# ESP32-P4-LP register map
Vendor: ESPRESSIF SYSTEMS (SHANGHAI) CO., LTD.; Series: ESP32 P-Series; File version: 3
CPU: RV32IMAC r0p0, little endian, no MPU, no FPU, 0 interrupt priority bits
Address unit: 32 bits
Registers are 32-bit, read-write, reset 0x0 unless marked. A register's access mark holds for its fields unless they carry their own. Offsets are from the block's base; [hi:lo] are bit positions; {n}, {i} and the like mark numbered series.

## PMU
Base 0x50115000
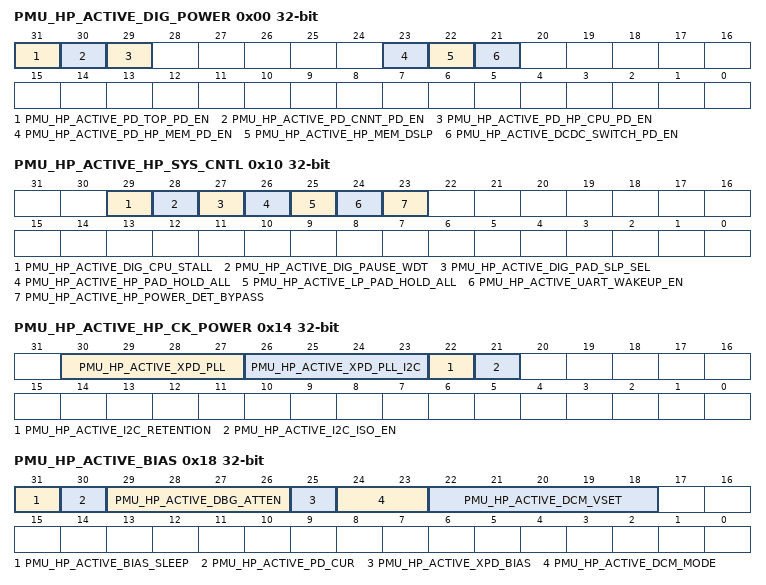
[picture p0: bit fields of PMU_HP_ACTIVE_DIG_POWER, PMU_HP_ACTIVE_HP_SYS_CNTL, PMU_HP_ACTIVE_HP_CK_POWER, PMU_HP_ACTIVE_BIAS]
0x00 PMU_HP_ACTIVE_DIG_POWER
  [31] PMU_HP_ACTIVE_PD_TOP_PD_EN, [30] PMU_HP_ACTIVE_PD_CNNT_PD_EN, [29] PMU_HP_ACTIVE_PD_HP_CPU_PD_EN, [23] PMU_HP_ACTIVE_PD_HP_MEM_PD_EN, [22] PMU_HP_ACTIVE_HP_MEM_DSLP, [21] PMU_HP_ACTIVE_DCDC_SWITCH_PD_EN
0x04 PMU_HP_ACTIVE_ICG_HP_FUNC
  [31:0] PMU_HP_ACTIVE_DIG_ICG_FUNC_EN
0x08 PMU_HP_ACTIVE_ICG_HP_APB
  [31:0] PMU_HP_ACTIVE_DIG_ICG_APB_EN
0x0C PMU_HP_ACTIVE_ICG_MODEM
  [31:30] PMU_HP_ACTIVE_DIG_ICG_MODEM_CODE
0x10 PMU_HP_ACTIVE_HP_SYS_CNTL
  [29] PMU_HP_ACTIVE_DIG_CPU_STALL, [28] PMU_HP_ACTIVE_DIG_PAUSE_WDT, [27] PMU_HP_ACTIVE_DIG_PAD_SLP_SEL, [26] PMU_HP_ACTIVE_HP_PAD_HOLD_ALL, [25] PMU_HP_ACTIVE_LP_PAD_HOLD_ALL, [24] PMU_HP_ACTIVE_UART_WAKEUP_EN, [23] PMU_HP_ACTIVE_HP_POWER_DET_BYPASS
0x14 PMU_HP_ACTIVE_HP_CK_POWER
  [30:27] PMU_HP_ACTIVE_XPD_PLL, [26:23] PMU_HP_ACTIVE_XPD_PLL_I2C, [22] PMU_HP_ACTIVE_I2C_RETENTION, [21] PMU_HP_ACTIVE_I2C_ISO_EN
0x18 PMU_HP_ACTIVE_BIAS
  [31] PMU_HP_ACTIVE_BIAS_SLEEP, [30] PMU_HP_ACTIVE_PD_CUR, [29:26] PMU_HP_ACTIVE_DBG_ATTEN, [25] PMU_HP_ACTIVE_XPD_BIAS, [24:23] PMU_HP_ACTIVE_DCM_MODE, [22:18] PMU_HP_ACTIVE_DCM_VSET
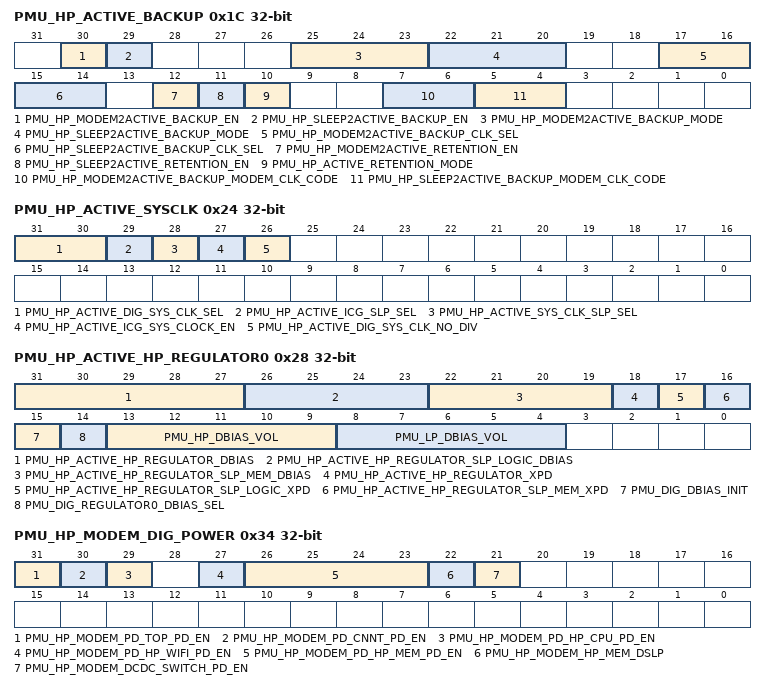
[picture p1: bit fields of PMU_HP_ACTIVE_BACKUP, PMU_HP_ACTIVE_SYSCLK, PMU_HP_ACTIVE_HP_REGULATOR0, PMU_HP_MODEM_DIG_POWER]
0x1C PMU_HP_ACTIVE_BACKUP
  [30] PMU_HP_MODEM2ACTIVE_BACKUP_EN, [29] PMU_HP_SLEEP2ACTIVE_BACKUP_EN, [25:23] PMU_HP_MODEM2ACTIVE_BACKUP_MODE, [22:20] PMU_HP_SLEEP2ACTIVE_BACKUP_MODE, [17:16] PMU_HP_MODEM2ACTIVE_BACKUP_CLK_SEL, [15:14] PMU_HP_SLEEP2ACTIVE_BACKUP_CLK_SEL, [12] PMU_HP_MODEM2ACTIVE_RETENTION_EN, [11] PMU_HP_SLEEP2ACTIVE_RETENTION_EN, [10] PMU_HP_ACTIVE_RETENTION_MODE, [7:6] PMU_HP_MODEM2ACTIVE_BACKUP_MODEM_CLK_CODE, [5:4] PMU_HP_SLEEP2ACTIVE_BACKUP_MODEM_CLK_CODE
0x20 PMU_HP_ACTIVE_BACKUP_CLK
  [31:0] PMU_HP_ACTIVE_BACKUP_ICG_FUNC_EN
0x24 PMU_HP_ACTIVE_SYSCLK
  [31:30] PMU_HP_ACTIVE_DIG_SYS_CLK_SEL, [29] PMU_HP_ACTIVE_ICG_SLP_SEL, [28] PMU_HP_ACTIVE_SYS_CLK_SLP_SEL, [27] PMU_HP_ACTIVE_ICG_SYS_CLOCK_EN, [26] PMU_HP_ACTIVE_DIG_SYS_CLK_NO_DIV
0x28 PMU_HP_ACTIVE_HP_REGULATOR0 access per field
  [31:27] PMU_HP_ACTIVE_HP_REGULATOR_DBIAS rw, [26:23] PMU_HP_ACTIVE_HP_REGULATOR_SLP_LOGIC_DBIAS rw, [22:19] PMU_HP_ACTIVE_HP_REGULATOR_SLP_MEM_DBIAS rw, [18] PMU_HP_ACTIVE_HP_REGULATOR_XPD rw, [17] PMU_HP_ACTIVE_HP_REGULATOR_SLP_LOGIC_XPD rw, [16] PMU_HP_ACTIVE_HP_REGULATOR_SLP_MEM_XPD rw, [15] PMU_DIG_DBIAS_INIT wo, [14] PMU_DIG_REGULATOR0_DBIAS_SEL rw, [13:9] PMU_HP_DBIAS_VOL ro, [8:4] PMU_LP_DBIAS_VOL ro
0x2C PMU_HP_ACTIVE_HP_REGULATOR1
  [31:26] PMU_HP_ACTIVE_HP_REGULATOR_DRV_B
0x30 PMU_HP_ACTIVE_XTAL
  [31] PMU_HP_ACTIVE_XPD_XTAL
0x34 PMU_HP_MODEM_DIG_POWER access per field
  [31] PMU_HP_MODEM_PD_TOP_PD_EN wo, [30] PMU_HP_MODEM_PD_CNNT_PD_EN wo, [29] PMU_HP_MODEM_PD_HP_CPU_PD_EN wo, [27] PMU_HP_MODEM_PD_HP_WIFI_PD_EN wo, [26:23] PMU_HP_MODEM_PD_HP_MEM_PD_EN wo, [22] PMU_HP_MODEM_HP_MEM_DSLP wo, [21] PMU_HP_MODEM_DCDC_SWITCH_PD_EN rw
0x38 PMU_HP_MODEM_ICG_HP_FUNC wo
  [31:0] PMU_HP_MODEM_DIG_ICG_FUNC_EN
0x3C PMU_HP_MODEM_ICG_HP_APB wo
  [31:0] PMU_HP_MODEM_DIG_ICG_APB_EN
0x40 PMU_HP_MODEM_ICG_MODEM wo
  [31:30] PMU_HP_MODEM_DIG_ICG_MODEM_CODE
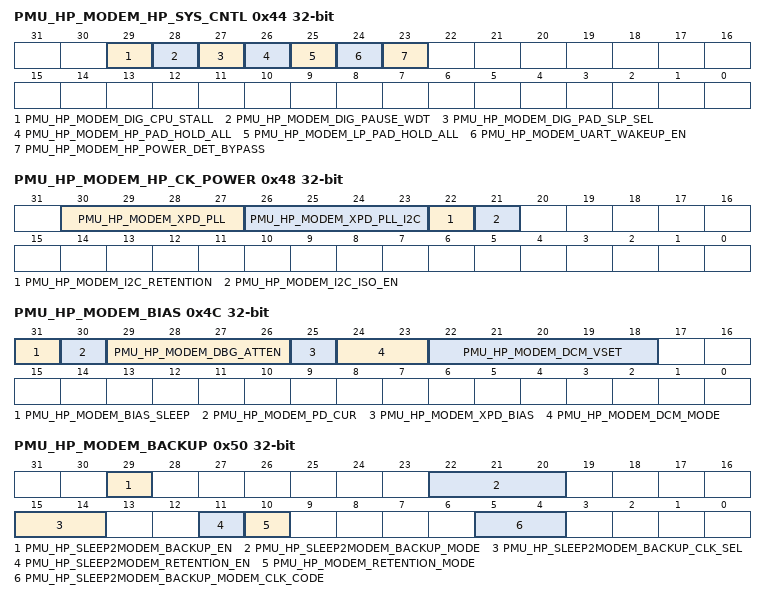
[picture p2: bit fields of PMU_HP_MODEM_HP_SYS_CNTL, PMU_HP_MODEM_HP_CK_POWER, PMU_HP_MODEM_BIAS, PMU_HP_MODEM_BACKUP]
0x44 PMU_HP_MODEM_HP_SYS_CNTL wo
  [29] PMU_HP_MODEM_DIG_CPU_STALL, [28] PMU_HP_MODEM_DIG_PAUSE_WDT, [27] PMU_HP_MODEM_DIG_PAD_SLP_SEL, [26] PMU_HP_MODEM_HP_PAD_HOLD_ALL, [25] PMU_HP_MODEM_LP_PAD_HOLD_ALL, [24] PMU_HP_MODEM_UART_WAKEUP_EN, [23] PMU_HP_MODEM_HP_POWER_DET_BYPASS
0x48 PMU_HP_MODEM_HP_CK_POWER wo
  [30:27] PMU_HP_MODEM_XPD_PLL, [26:23] PMU_HP_MODEM_XPD_PLL_I2C, [22] PMU_HP_MODEM_I2C_RETENTION, [21] PMU_HP_MODEM_I2C_ISO_EN
0x4C PMU_HP_MODEM_BIAS wo
  [31] PMU_HP_MODEM_BIAS_SLEEP, [30] PMU_HP_MODEM_PD_CUR, [29:26] PMU_HP_MODEM_DBG_ATTEN, [25] PMU_HP_MODEM_XPD_BIAS, [24:23] PMU_HP_MODEM_DCM_MODE, [22:18] PMU_HP_MODEM_DCM_VSET
0x50 PMU_HP_MODEM_BACKUP wo
  [29] PMU_HP_SLEEP2MODEM_BACKUP_EN, [22:20] PMU_HP_SLEEP2MODEM_BACKUP_MODE, [15:14] PMU_HP_SLEEP2MODEM_BACKUP_CLK_SEL, [11] PMU_HP_SLEEP2MODEM_RETENTION_EN, [10] PMU_HP_MODEM_RETENTION_MODE, [5:4] PMU_HP_SLEEP2MODEM_BACKUP_MODEM_CLK_CODE
0x54 PMU_HP_MODEM_BACKUP_CLK wo
  [31:0] PMU_HP_MODEM_BACKUP_ICG_FUNC_EN
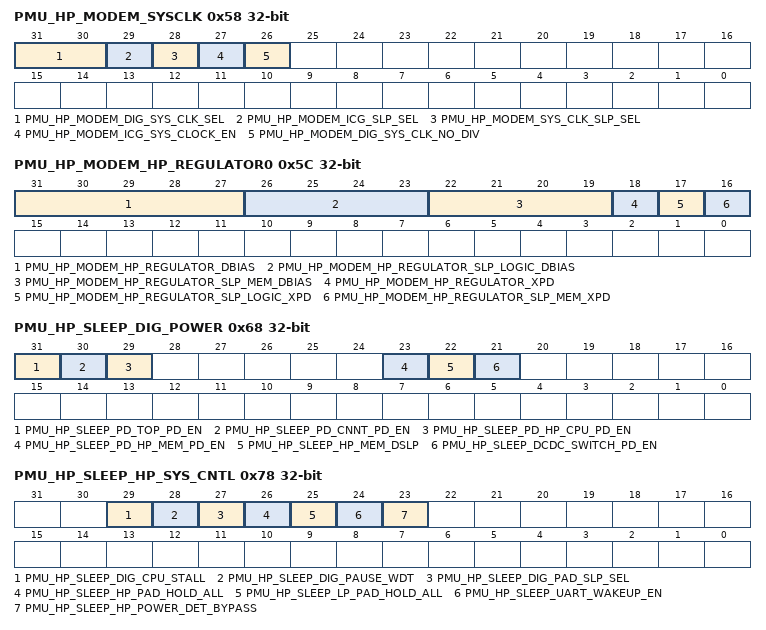
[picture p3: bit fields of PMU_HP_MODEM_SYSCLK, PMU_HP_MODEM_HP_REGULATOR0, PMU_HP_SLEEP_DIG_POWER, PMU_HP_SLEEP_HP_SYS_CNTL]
0x58 PMU_HP_MODEM_SYSCLK wo
  [31:30] PMU_HP_MODEM_DIG_SYS_CLK_SEL, [29] PMU_HP_MODEM_ICG_SLP_SEL, [28] PMU_HP_MODEM_SYS_CLK_SLP_SEL, [27] PMU_HP_MODEM_ICG_SYS_CLOCK_EN, [26] PMU_HP_MODEM_DIG_SYS_CLK_NO_DIV
0x5C PMU_HP_MODEM_HP_REGULATOR0 wo
  [31:27] PMU_HP_MODEM_HP_REGULATOR_DBIAS, [26:23] PMU_HP_MODEM_HP_REGULATOR_SLP_LOGIC_DBIAS, [22:19] PMU_HP_MODEM_HP_REGULATOR_SLP_MEM_DBIAS, [18] PMU_HP_MODEM_HP_REGULATOR_XPD, [17] PMU_HP_MODEM_HP_REGULATOR_SLP_LOGIC_XPD, [16] PMU_HP_MODEM_HP_REGULATOR_SLP_MEM_XPD
0x60 PMU_HP_MODEM_HP_REGULATOR1 wo
  [31:8] PMU_HP_MODEM_HP_REGULATOR_DRV_B
0x64 PMU_HP_MODEM_XTAL wo
  [31] PMU_HP_MODEM_XPD_XTAL
0x68 PMU_HP_SLEEP_DIG_POWER
  [31] PMU_HP_SLEEP_PD_TOP_PD_EN, [30] PMU_HP_SLEEP_PD_CNNT_PD_EN, [29] PMU_HP_SLEEP_PD_HP_CPU_PD_EN, [23] PMU_HP_SLEEP_PD_HP_MEM_PD_EN, [22] PMU_HP_SLEEP_HP_MEM_DSLP, [21] PMU_HP_SLEEP_DCDC_SWITCH_PD_EN
0x6C PMU_HP_SLEEP_ICG_HP_FUNC
  [31:0] PMU_HP_SLEEP_DIG_ICG_FUNC_EN
0x70 PMU_HP_SLEEP_ICG_HP_APB
  [31:0] PMU_HP_SLEEP_DIG_ICG_APB_EN
0x74 PMU_HP_SLEEP_ICG_MODEM
  [31:30] PMU_HP_SLEEP_DIG_ICG_MODEM_CODE
0x78 PMU_HP_SLEEP_HP_SYS_CNTL
  [29] PMU_HP_SLEEP_DIG_CPU_STALL, [28] PMU_HP_SLEEP_DIG_PAUSE_WDT, [27] PMU_HP_SLEEP_DIG_PAD_SLP_SEL, [26] PMU_HP_SLEEP_HP_PAD_HOLD_ALL, [25] PMU_HP_SLEEP_LP_PAD_HOLD_ALL, [24] PMU_HP_SLEEP_UART_WAKEUP_EN, [23] PMU_HP_SLEEP_HP_POWER_DET_BYPASS
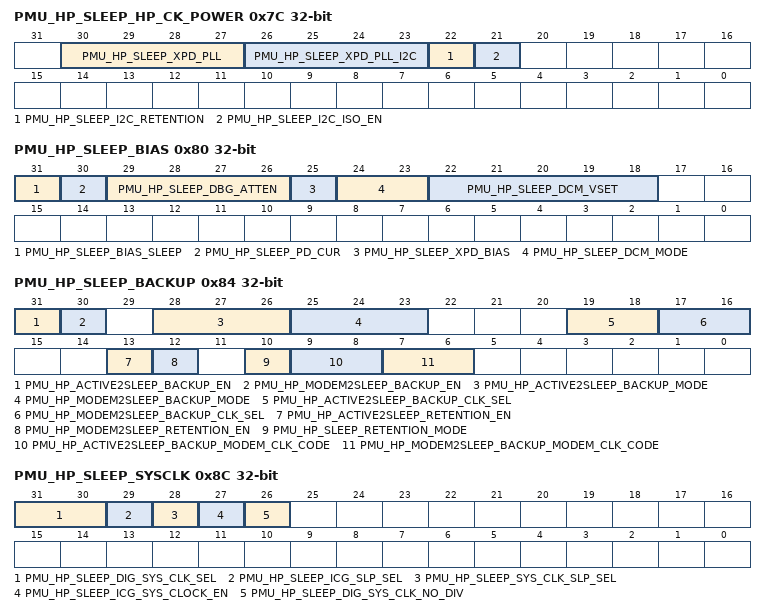
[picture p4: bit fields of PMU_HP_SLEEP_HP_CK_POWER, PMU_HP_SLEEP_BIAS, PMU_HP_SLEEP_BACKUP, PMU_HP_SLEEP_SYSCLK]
0x7C PMU_HP_SLEEP_HP_CK_POWER
  [30:27] PMU_HP_SLEEP_XPD_PLL, [26:23] PMU_HP_SLEEP_XPD_PLL_I2C, [22] PMU_HP_SLEEP_I2C_RETENTION, [21] PMU_HP_SLEEP_I2C_ISO_EN
0x80 PMU_HP_SLEEP_BIAS
  [31] PMU_HP_SLEEP_BIAS_SLEEP, [30] PMU_HP_SLEEP_PD_CUR, [29:26] PMU_HP_SLEEP_DBG_ATTEN, [25] PMU_HP_SLEEP_XPD_BIAS, [24:23] PMU_HP_SLEEP_DCM_MODE, [22:18] PMU_HP_SLEEP_DCM_VSET
0x84 PMU_HP_SLEEP_BACKUP
  [31] PMU_HP_ACTIVE2SLEEP_BACKUP_EN, [30] PMU_HP_MODEM2SLEEP_BACKUP_EN, [28:26] PMU_HP_ACTIVE2SLEEP_BACKUP_MODE, [25:23] PMU_HP_MODEM2SLEEP_BACKUP_MODE, [19:18] PMU_HP_ACTIVE2SLEEP_BACKUP_CLK_SEL, [17:16] PMU_HP_MODEM2SLEEP_BACKUP_CLK_SEL, [13] PMU_HP_ACTIVE2SLEEP_RETENTION_EN, [12] PMU_HP_MODEM2SLEEP_RETENTION_EN, [10] PMU_HP_SLEEP_RETENTION_MODE, [9:8] PMU_HP_ACTIVE2SLEEP_BACKUP_MODEM_CLK_CODE, [7:6] PMU_HP_MODEM2SLEEP_BACKUP_MODEM_CLK_CODE
0x88 PMU_HP_SLEEP_BACKUP_CLK
  [31:0] PMU_HP_SLEEP_BACKUP_ICG_FUNC_EN
0x8C PMU_HP_SLEEP_SYSCLK
  [31:30] PMU_HP_SLEEP_DIG_SYS_CLK_SEL, [29] PMU_HP_SLEEP_ICG_SLP_SEL, [28] PMU_HP_SLEEP_SYS_CLK_SLP_SEL, [27] PMU_HP_SLEEP_ICG_SYS_CLOCK_EN, [26] PMU_HP_SLEEP_DIG_SYS_CLK_NO_DIV
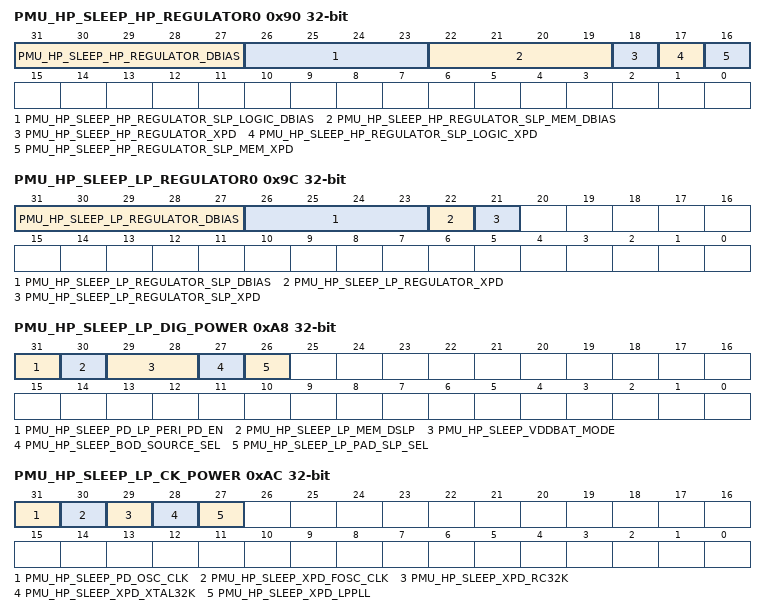
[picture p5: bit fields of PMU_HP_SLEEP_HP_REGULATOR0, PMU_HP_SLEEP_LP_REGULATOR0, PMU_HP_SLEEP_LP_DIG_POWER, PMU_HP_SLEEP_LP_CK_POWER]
0x90 PMU_HP_SLEEP_HP_REGULATOR0
  [31:27] PMU_HP_SLEEP_HP_REGULATOR_DBIAS, [26:23] PMU_HP_SLEEP_HP_REGULATOR_SLP_LOGIC_DBIAS, [22:19] PMU_HP_SLEEP_HP_REGULATOR_SLP_MEM_DBIAS, [18] PMU_HP_SLEEP_HP_REGULATOR_XPD, [17] PMU_HP_SLEEP_HP_REGULATOR_SLP_LOGIC_XPD, [16] PMU_HP_SLEEP_HP_REGULATOR_SLP_MEM_XPD
0x94 PMU_HP_SLEEP_HP_REGULATOR1
  [31:26] PMU_HP_SLEEP_HP_REGULATOR_DRV_B
0x98 PMU_HP_SLEEP_XTAL
  [31] PMU_HP_SLEEP_XPD_XTAL
0x9C PMU_HP_SLEEP_LP_REGULATOR0
  [31:27] PMU_HP_SLEEP_LP_REGULATOR_DBIAS, [26:23] PMU_HP_SLEEP_LP_REGULATOR_SLP_DBIAS, [22] PMU_HP_SLEEP_LP_REGULATOR_XPD, [21] PMU_HP_SLEEP_LP_REGULATOR_SLP_XPD
0xA0 PMU_HP_SLEEP_LP_REGULATOR1
  [31:26] PMU_HP_SLEEP_LP_REGULATOR_DRV_B
0xA8 PMU_HP_SLEEP_LP_DIG_POWER
  [31] PMU_HP_SLEEP_PD_LP_PERI_PD_EN, [30] PMU_HP_SLEEP_LP_MEM_DSLP, [29:28] PMU_HP_SLEEP_VDDBAT_MODE, [27] PMU_HP_SLEEP_BOD_SOURCE_SEL, [26] PMU_HP_SLEEP_LP_PAD_SLP_SEL
0xAC PMU_HP_SLEEP_LP_CK_POWER
  [31] PMU_HP_SLEEP_PD_OSC_CLK, [30] PMU_HP_SLEEP_XPD_FOSC_CLK, [29] PMU_HP_SLEEP_XPD_RC32K, [28] PMU_HP_SLEEP_XPD_XTAL32K, [27] PMU_HP_SLEEP_XPD_LPPLL
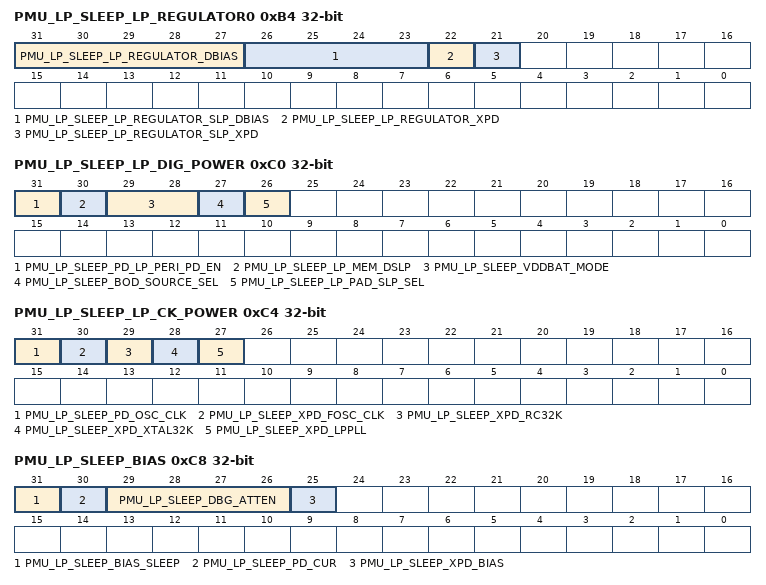
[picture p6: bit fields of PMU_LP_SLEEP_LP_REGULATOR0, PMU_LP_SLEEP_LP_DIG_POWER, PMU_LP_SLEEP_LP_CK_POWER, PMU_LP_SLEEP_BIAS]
0xB4 PMU_LP_SLEEP_LP_REGULATOR0
  [31:27] PMU_LP_SLEEP_LP_REGULATOR_DBIAS, [26:23] PMU_LP_SLEEP_LP_REGULATOR_SLP_DBIAS, [22] PMU_LP_SLEEP_LP_REGULATOR_XPD, [21] PMU_LP_SLEEP_LP_REGULATOR_SLP_XPD
0xB8 PMU_LP_SLEEP_LP_REGULATOR1
  [31:26] PMU_LP_SLEEP_LP_REGULATOR_DRV_B
0xBC PMU_LP_SLEEP_XTAL
  [31] PMU_LP_SLEEP_XPD_XTAL
0xC0 PMU_LP_SLEEP_LP_DIG_POWER
  [31] PMU_LP_SLEEP_PD_LP_PERI_PD_EN, [30] PMU_LP_SLEEP_LP_MEM_DSLP, [29:28] PMU_LP_SLEEP_VDDBAT_MODE, [27] PMU_LP_SLEEP_BOD_SOURCE_SEL, [26] PMU_LP_SLEEP_LP_PAD_SLP_SEL
0xC4 PMU_LP_SLEEP_LP_CK_POWER
  [31] PMU_LP_SLEEP_PD_OSC_CLK, [30] PMU_LP_SLEEP_XPD_FOSC_CLK, [29] PMU_LP_SLEEP_XPD_RC32K, [28] PMU_LP_SLEEP_XPD_XTAL32K, [27] PMU_LP_SLEEP_XPD_LPPLL
0xC8 PMU_LP_SLEEP_BIAS
  [31] PMU_LP_SLEEP_BIAS_SLEEP, [30] PMU_LP_SLEEP_PD_CUR, [29:26] PMU_LP_SLEEP_DBG_ATTEN, [25] PMU_LP_SLEEP_XPD_BIAS
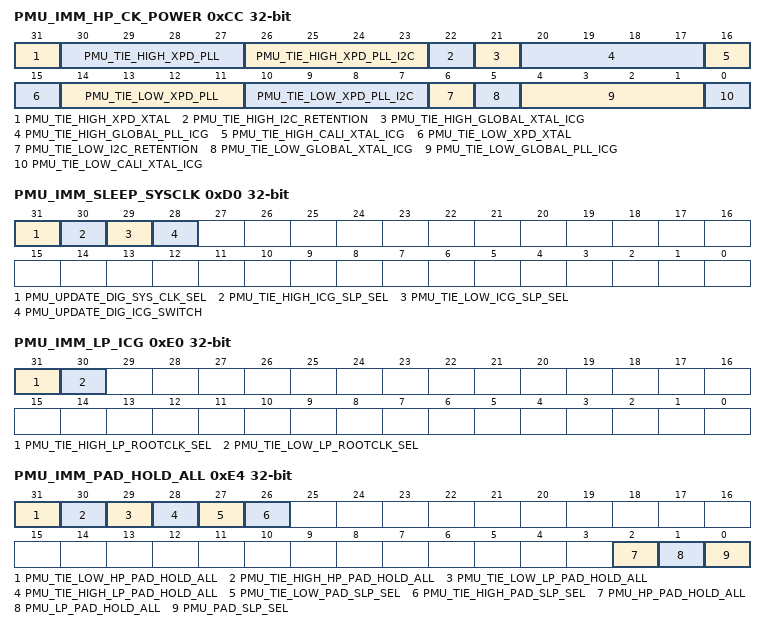
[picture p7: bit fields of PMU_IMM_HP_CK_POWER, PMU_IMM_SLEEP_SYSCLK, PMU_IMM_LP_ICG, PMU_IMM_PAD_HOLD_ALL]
0xCC PMU_IMM_HP_CK_POWER access per field
  [31] PMU_TIE_HIGH_XPD_XTAL wo, [30:27] PMU_TIE_HIGH_XPD_PLL wo, [26:23] PMU_TIE_HIGH_XPD_PLL_I2C wo, [22] PMU_TIE_HIGH_I2C_RETENTION wo, [21] PMU_TIE_HIGH_GLOBAL_XTAL_ICG wo, [20:17] PMU_TIE_HIGH_GLOBAL_PLL_ICG wo, [16] PMU_TIE_HIGH_CALI_XTAL_ICG rw, [15] PMU_TIE_LOW_XPD_XTAL wo, [14:11] PMU_TIE_LOW_XPD_PLL wo, [10:7] PMU_TIE_LOW_XPD_PLL_I2C wo, [6] PMU_TIE_LOW_I2C_RETENTION wo, [5] PMU_TIE_LOW_GLOBAL_XTAL_ICG wo, [4:1] PMU_TIE_LOW_GLOBAL_PLL_ICG wo, [0] PMU_TIE_LOW_CALI_XTAL_ICG rw
0xD0 PMU_IMM_SLEEP_SYSCLK wo
  [31] PMU_UPDATE_DIG_SYS_CLK_SEL, [30] PMU_TIE_HIGH_ICG_SLP_SEL, [29] PMU_TIE_LOW_ICG_SLP_SEL, [28] PMU_UPDATE_DIG_ICG_SWITCH
0xD4 PMU_IMM_HP_FUNC_ICG wo
  [31] PMU_UPDATE_DIG_ICG_FUNC_EN
0xD8 PMU_IMM_HP_APB_ICG wo
  [31] PMU_UPDATE_DIG_ICG_APB_EN
0xDC PMU_IMM_MODEM_ICG wo
  [31] PMU_UPDATE_DIG_ICG_MODEM_EN
0xE0 PMU_IMM_LP_ICG wo
  [31] PMU_TIE_HIGH_LP_ROOTCLK_SEL, [30] PMU_TIE_LOW_LP_ROOTCLK_SEL
0xE4 PMU_IMM_PAD_HOLD_ALL access per field
  [31] PMU_TIE_LOW_HP_PAD_HOLD_ALL wo, [30] PMU_TIE_HIGH_HP_PAD_HOLD_ALL wo, [29] PMU_TIE_LOW_LP_PAD_HOLD_ALL wo, [28] PMU_TIE_HIGH_LP_PAD_HOLD_ALL wo, [27] PMU_TIE_LOW_PAD_SLP_SEL wo, [26] PMU_TIE_HIGH_PAD_SLP_SEL wo, [2] PMU_HP_PAD_HOLD_ALL ro, [1] PMU_LP_PAD_HOLD_ALL ro, [0] PMU_PAD_SLP_SEL ro
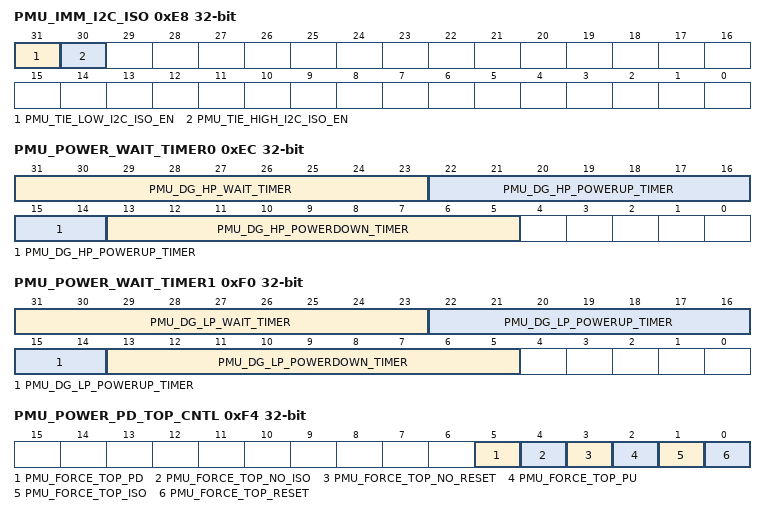
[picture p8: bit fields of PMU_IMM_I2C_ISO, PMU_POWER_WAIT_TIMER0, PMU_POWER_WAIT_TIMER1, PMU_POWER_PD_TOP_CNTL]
0xE8 PMU_IMM_I2C_ISO wo
  [31] PMU_TIE_LOW_I2C_ISO_EN, [30] PMU_TIE_HIGH_I2C_ISO_EN
0xEC PMU_POWER_WAIT_TIMER0
  [31:23] PMU_DG_HP_WAIT_TIMER, [22:14] PMU_DG_HP_POWERUP_TIMER, [13:5] PMU_DG_HP_POWERDOWN_TIMER
0xF0 PMU_POWER_WAIT_TIMER1
  [31:23] PMU_DG_LP_WAIT_TIMER, [22:14] PMU_DG_LP_POWERUP_TIMER, [13:5] PMU_DG_LP_POWERDOWN_TIMER
0xF4 PMU_POWER_PD_TOP_CNTL
  [5] PMU_FORCE_TOP_PD, [4] PMU_FORCE_TOP_NO_ISO, [3] PMU_FORCE_TOP_NO_RESET, [2] PMU_FORCE_TOP_PU, [1] PMU_FORCE_TOP_ISO, [0] PMU_FORCE_TOP_RESET
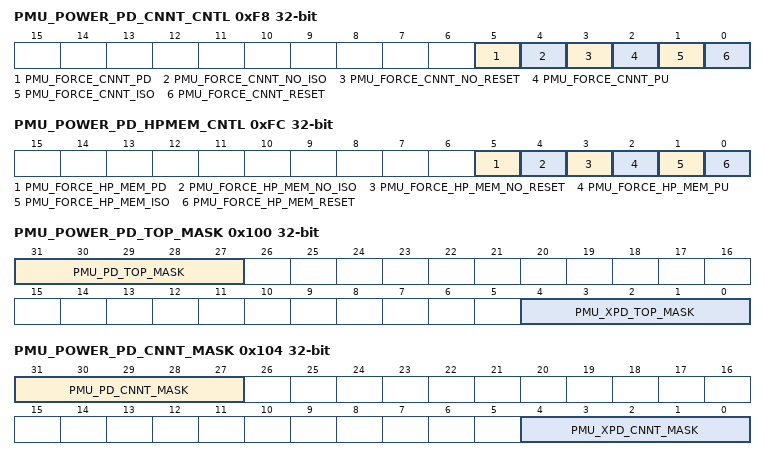
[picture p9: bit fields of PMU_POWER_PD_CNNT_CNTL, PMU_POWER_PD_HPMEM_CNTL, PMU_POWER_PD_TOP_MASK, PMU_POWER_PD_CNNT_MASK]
0xF8 PMU_POWER_PD_CNNT_CNTL
  [5] PMU_FORCE_CNNT_PD, [4] PMU_FORCE_CNNT_NO_ISO, [3] PMU_FORCE_CNNT_NO_RESET, [2] PMU_FORCE_CNNT_PU, [1] PMU_FORCE_CNNT_ISO, [0] PMU_FORCE_CNNT_RESET
0xFC PMU_POWER_PD_HPMEM_CNTL
  [5] PMU_FORCE_HP_MEM_PD, [4] PMU_FORCE_HP_MEM_NO_ISO, [3] PMU_FORCE_HP_MEM_NO_RESET, [2] PMU_FORCE_HP_MEM_PU, [1] PMU_FORCE_HP_MEM_ISO, [0] PMU_FORCE_HP_MEM_RESET
0x100 PMU_POWER_PD_TOP_MASK
  [31:27] PMU_PD_TOP_MASK, [4:0] PMU_XPD_TOP_MASK
0x104 PMU_POWER_PD_CNNT_MASK
  [31:27] PMU_PD_CNNT_MASK, [4:0] PMU_XPD_CNNT_MASK
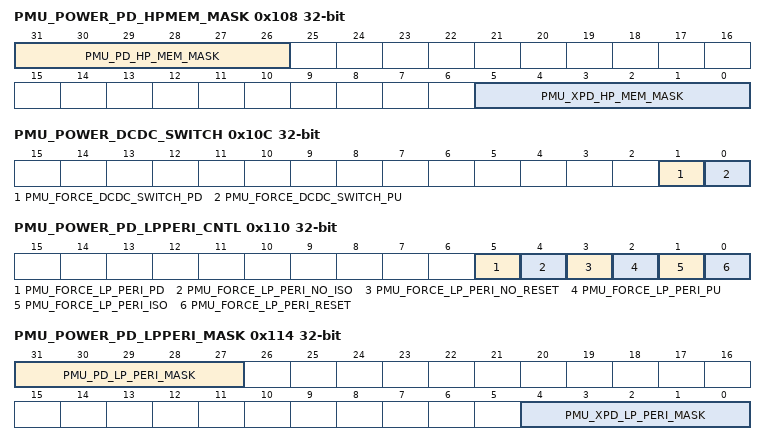
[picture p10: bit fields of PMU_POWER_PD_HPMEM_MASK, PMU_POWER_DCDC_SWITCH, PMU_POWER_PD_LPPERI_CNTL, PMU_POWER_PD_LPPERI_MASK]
0x108 PMU_POWER_PD_HPMEM_MASK
  [31:26] PMU_PD_HP_MEM_MASK, [5:0] PMU_XPD_HP_MEM_MASK
0x10C PMU_POWER_DCDC_SWITCH
  [1] PMU_FORCE_DCDC_SWITCH_PD, [0] PMU_FORCE_DCDC_SWITCH_PU
0x110 PMU_POWER_PD_LPPERI_CNTL
  [5] PMU_FORCE_LP_PERI_PD, [4] PMU_FORCE_LP_PERI_NO_ISO, [3] PMU_FORCE_LP_PERI_NO_RESET, [2] PMU_FORCE_LP_PERI_PU, [1] PMU_FORCE_LP_PERI_ISO, [0] PMU_FORCE_LP_PERI_RESET
0x114 PMU_POWER_PD_LPPERI_MASK
  [31:27] PMU_PD_LP_PERI_MASK, [4:0] PMU_XPD_LP_PERI_MASK
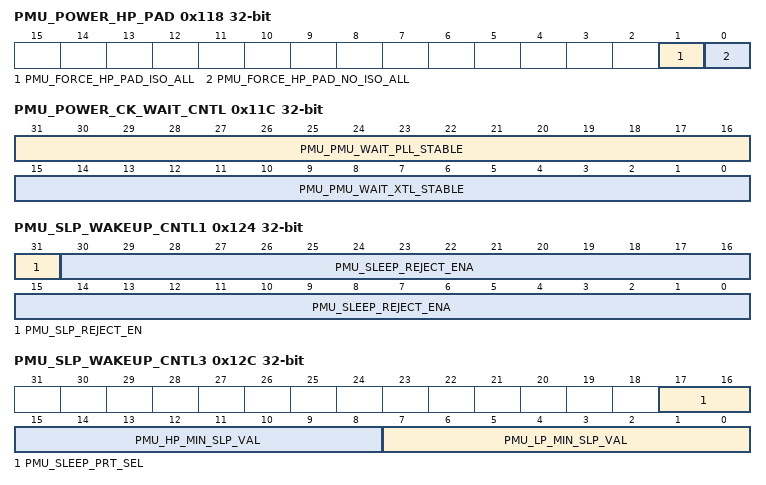
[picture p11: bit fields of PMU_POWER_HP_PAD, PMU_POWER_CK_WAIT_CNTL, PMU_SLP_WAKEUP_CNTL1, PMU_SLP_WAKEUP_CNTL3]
0x118 PMU_POWER_HP_PAD
  [1] PMU_FORCE_HP_PAD_ISO_ALL, [0] PMU_FORCE_HP_PAD_NO_ISO_ALL
0x11C PMU_POWER_CK_WAIT_CNTL
  [31:16] PMU_PMU_WAIT_PLL_STABLE, [15:0] PMU_PMU_WAIT_XTL_STABLE
0x120 PMU_SLP_WAKEUP_CNTL0 wo
  [31] PMU_SLEEP_REQ
0x124 PMU_SLP_WAKEUP_CNTL1
  [31] PMU_SLP_REJECT_EN, [30:0] PMU_SLEEP_REJECT_ENA
0x128 PMU_SLP_WAKEUP_CNTL2
  [30:0] PMU_WAKEUP_ENA
0x12C PMU_SLP_WAKEUP_CNTL3
  [17:16] PMU_SLEEP_PRT_SEL, [15:8] PMU_HP_MIN_SLP_VAL, [7:0] PMU_LP_MIN_SLP_VAL
0x130 PMU_SLP_WAKEUP_CNTL4 wo
  [31] PMU_SLP_REJECT_CAUSE_CLR
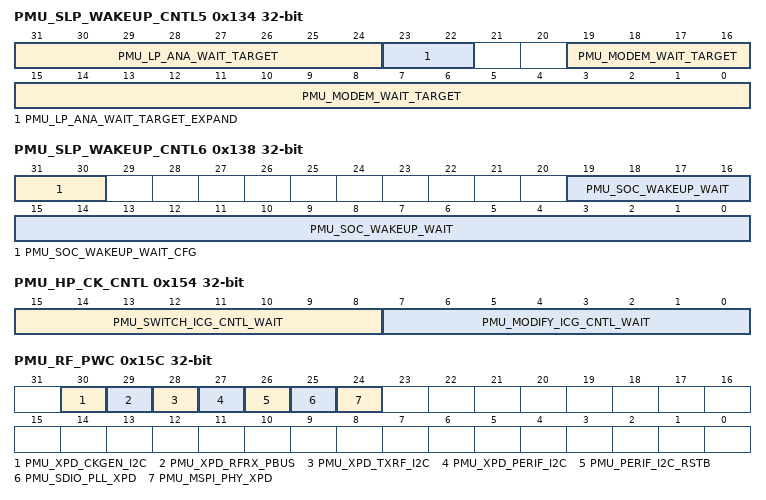
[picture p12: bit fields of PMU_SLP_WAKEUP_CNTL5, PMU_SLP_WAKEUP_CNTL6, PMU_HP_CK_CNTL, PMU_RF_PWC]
0x134 PMU_SLP_WAKEUP_CNTL5
  [31:24] PMU_LP_ANA_WAIT_TARGET, [23:22] PMU_LP_ANA_WAIT_TARGET_EXPAND, [19:0] PMU_MODEM_WAIT_TARGET
0x138 PMU_SLP_WAKEUP_CNTL6
  [31:30] PMU_SOC_WAKEUP_WAIT_CFG, [19:0] PMU_SOC_WAKEUP_WAIT
0x13C PMU_SLP_WAKEUP_CNTL7
  [31:16] PMU_ANA_WAIT_TARGET
0x140 PMU_SLP_WAKEUP_CNTL8
  [31] PMU_LP_LITE_WAKEUP_ENA
0x144 PMU_SLP_WAKEUP_STATUS0 ro
  [30:0] PMU_WAKEUP_CAUSE
0x148 PMU_SLP_WAKEUP_STATUS1 ro
  [30:0] PMU_REJECT_CAUSE
0x14C PMU_SLP_WAKEUP_STATUS2 ro
  [31] PMU_LP_LITE_WAKEUP_CAUSE
0x150 PMU_HP_CK_POWERON
  [7:0] PMU_I2C_POR_WAIT_TARGET
0x154 PMU_HP_CK_CNTL
  [15:8] PMU_SWITCH_ICG_CNTL_WAIT, [7:0] PMU_MODIFY_ICG_CNTL_WAIT
0x158 PMU_POR_STATUS ro
  [31] PMU_POR_DONE
0x15C PMU_RF_PWC
  [30] PMU_XPD_CKGEN_I2C, [29] PMU_XPD_RFRX_PBUS, [28] PMU_XPD_TXRF_I2C, [27] PMU_XPD_PERIF_I2C, [26] PMU_PERIF_I2C_RSTB, [25] PMU_SDIO_PLL_XPD, [24] PMU_MSPI_PHY_XPD
0x160 PMU_BACKUP_CFG
  [31] PMU_BACKUP_SYS_CLK_NO_DIV
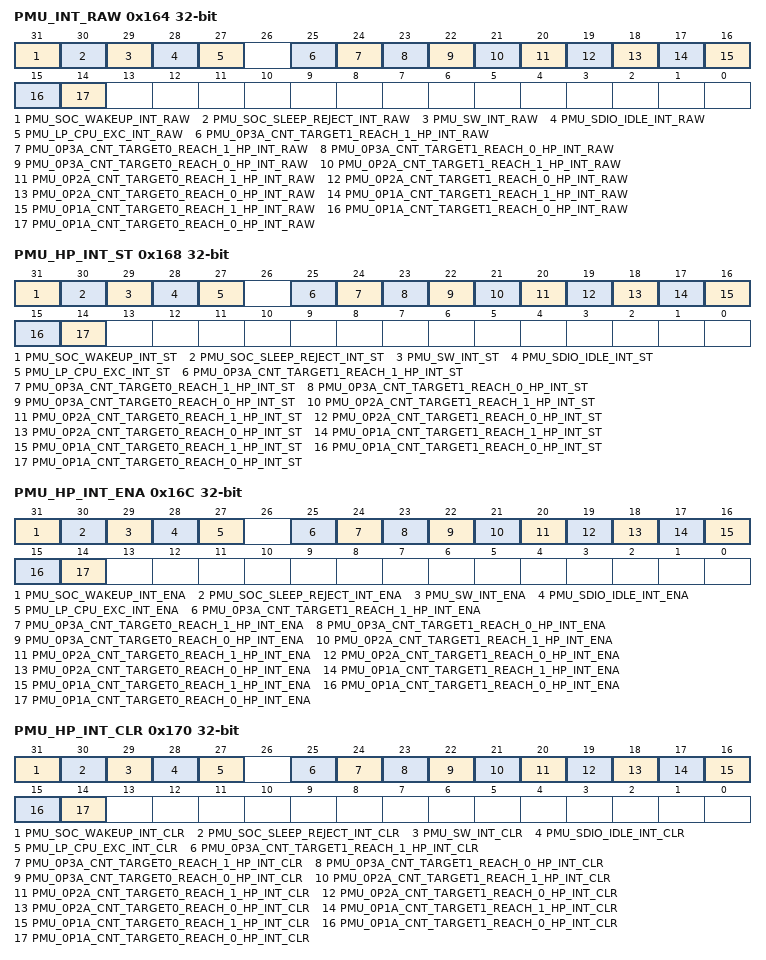
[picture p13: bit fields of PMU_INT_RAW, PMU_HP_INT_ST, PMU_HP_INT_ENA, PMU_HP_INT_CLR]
0x164 PMU_INT_RAW
  [31] PMU_SOC_WAKEUP_INT_RAW
  [30] PMU_SOC_SLEEP_REJECT_INT_RAW
  [29] PMU_SW_INT_RAW
  [28] PMU_SDIO_IDLE_INT_RAW
  [27] PMU_LP_CPU_EXC_INT_RAW
  [25] PMU_0P3A_CNT_TARGET1_REACH_1_HP_INT_RAW — reg_0p3a_1_counter after xpd reach target1
  [24] PMU_0P3A_CNT_TARGET0_REACH_1_HP_INT_RAW — reg_0p3a_0_counter after xpd reach target0
  [23] PMU_0P3A_CNT_TARGET1_REACH_0_HP_INT_RAW — reg_0p3a_1_counter after xpd reach target1
  [22] PMU_0P3A_CNT_TARGET0_REACH_0_HP_INT_RAW — reg_0p3a_0 counter after xpd reach target0
  [21] PMU_0P2A_CNT_TARGET1_REACH_1_HP_INT_RAW — reg_0p2a_1_counter after xpd reach target1
  [20] PMU_0P2A_CNT_TARGET0_REACH_1_HP_INT_RAW — reg_0p2a_0 counter after xpd reach target0
  [19] PMU_0P2A_CNT_TARGET1_REACH_0_HP_INT_RAW — reg_0p2a_1_counter after xpd reach target1
  [18] PMU_0P2A_CNT_TARGET0_REACH_0_HP_INT_RAW — reg_0p2a_0 counter after xpd reach target0
  [17] PMU_0P1A_CNT_TARGET1_REACH_1_HP_INT_RAW — reg_0p1a_1_counter after xpd reach target1
  [16] PMU_0P1A_CNT_TARGET0_REACH_1_HP_INT_RAW — reg_0p1a_0 counter after xpd reach target0
  [15] PMU_0P1A_CNT_TARGET1_REACH_0_HP_INT_RAW — reg_0p1a_1_counter after xpd reach target1
  [14] PMU_0P1A_CNT_TARGET0_REACH_0_HP_INT_RAW — reg_0p1a_0_counter after xpd reach target0
0x168 PMU_HP_INT_ST ro
  [31] PMU_SOC_WAKEUP_INT_ST
  [30] PMU_SOC_SLEEP_REJECT_INT_ST
  [29] PMU_SW_INT_ST
  [28] PMU_SDIO_IDLE_INT_ST
  [27] PMU_LP_CPU_EXC_INT_ST
  [25] PMU_0P3A_CNT_TARGET1_REACH_1_HP_INT_ST — reg_0p3a_1_counter after xpd reach target1
  [24] PMU_0P3A_CNT_TARGET0_REACH_1_HP_INT_ST — reg_0p3a_0_counter after xpd reach target0
  [23] PMU_0P3A_CNT_TARGET1_REACH_0_HP_INT_ST — reg_0p3a_1_counter after xpd reach target1
  [22] PMU_0P3A_CNT_TARGET0_REACH_0_HP_INT_ST — reg_0p3a_0 counter after xpd reach target0
  [21] PMU_0P2A_CNT_TARGET1_REACH_1_HP_INT_ST — reg_0p2a_1_counter after xpd reach target1
  [20] PMU_0P2A_CNT_TARGET0_REACH_1_HP_INT_ST — reg_0p2a_0 counter after xpd reach target0
  [19] PMU_0P2A_CNT_TARGET1_REACH_0_HP_INT_ST — reg_0p2a_1_counter after xpd reach target1
  [18] PMU_0P2A_CNT_TARGET0_REACH_0_HP_INT_ST — reg_0p2a_0 counter after xpd reach target0
  [17] PMU_0P1A_CNT_TARGET1_REACH_1_HP_INT_ST — reg_0p1a_1_counter after xpd reach target1
  [16] PMU_0P1A_CNT_TARGET0_REACH_1_HP_INT_ST — reg_0p1a_0 counter after xpd reach target0
  [15] PMU_0P1A_CNT_TARGET1_REACH_0_HP_INT_ST — reg_0p1a_1_counter after xpd reach target1
  [14] PMU_0P1A_CNT_TARGET0_REACH_0_HP_INT_ST — reg_0p1a_0_counter after xpd reach target0
0x16C PMU_HP_INT_ENA
  [31] PMU_SOC_WAKEUP_INT_ENA
  [30] PMU_SOC_SLEEP_REJECT_INT_ENA
  [29] PMU_SW_INT_ENA
  [28] PMU_SDIO_IDLE_INT_ENA
  [27] PMU_LP_CPU_EXC_INT_ENA
  [25] PMU_0P3A_CNT_TARGET1_REACH_1_HP_INT_ENA — reg_0p3a_1_counter after xpd reach target1
  [24] PMU_0P3A_CNT_TARGET0_REACH_1_HP_INT_ENA — reg_0p3a_0_counter after xpd reach target0
  [23] PMU_0P3A_CNT_TARGET1_REACH_0_HP_INT_ENA — reg_0p3a_1_counter after xpd reach target1
  [22] PMU_0P3A_CNT_TARGET0_REACH_0_HP_INT_ENA — reg_0p3a_0 counter after xpd reach target0
  [21] PMU_0P2A_CNT_TARGET1_REACH_1_HP_INT_ENA — reg_0p2a_1_counter after xpd reach target1
  [20] PMU_0P2A_CNT_TARGET0_REACH_1_HP_INT_ENA — reg_0p2a_0 counter after xpd reach target0
  [19] PMU_0P2A_CNT_TARGET1_REACH_0_HP_INT_ENA — reg_0p2a_1_counter after xpd reach target1
  [18] PMU_0P2A_CNT_TARGET0_REACH_0_HP_INT_ENA — reg_0p2a_0 counter after xpd reach target0
  [17] PMU_0P1A_CNT_TARGET1_REACH_1_HP_INT_ENA — reg_0p1a_1_counter after xpd reach target1
  [16] PMU_0P1A_CNT_TARGET0_REACH_1_HP_INT_ENA — reg_0p1a_0 counter after xpd reach target0
  [15] PMU_0P1A_CNT_TARGET1_REACH_0_HP_INT_ENA — reg_0p1a_1_counter after xpd reach target1
  [14] PMU_0P1A_CNT_TARGET0_REACH_0_HP_INT_ENA — reg_0p1a_0_counter after xpd reach target0
0x170 PMU_HP_INT_CLR wo
  [31] PMU_SOC_WAKEUP_INT_CLR
  [30] PMU_SOC_SLEEP_REJECT_INT_CLR
  [29] PMU_SW_INT_CLR
  [28] PMU_SDIO_IDLE_INT_CLR
  [27] PMU_LP_CPU_EXC_INT_CLR
  [25] PMU_0P3A_CNT_TARGET1_REACH_1_HP_INT_CLR — reg_0p3a_1_counter after xpd reach target1
  [24] PMU_0P3A_CNT_TARGET0_REACH_1_HP_INT_CLR — reg_0p3a_0_counter after xpd reach target0
  [23] PMU_0P3A_CNT_TARGET1_REACH_0_HP_INT_CLR — reg_0p3a_1_counter after xpd reach target1
  [22] PMU_0P3A_CNT_TARGET0_REACH_0_HP_INT_CLR — reg_0p3a_0 counter after xpd reach target0
  [21] PMU_0P2A_CNT_TARGET1_REACH_1_HP_INT_CLR — reg_0p2a_1_counter after xpd reach target1
  [20] PMU_0P2A_CNT_TARGET0_REACH_1_HP_INT_CLR — reg_0p2a_0 counter after xpd reach target0
  [19] PMU_0P2A_CNT_TARGET1_REACH_0_HP_INT_CLR — reg_0p2a_1_counter after xpd reach target1
  [18] PMU_0P2A_CNT_TARGET0_REACH_0_HP_INT_CLR — reg_0p2a_0 counter after xpd reach target0
  [17] PMU_0P1A_CNT_TARGET1_REACH_1_HP_INT_CLR — reg_0p1a_1_counter after xpd reach target1
  [16] PMU_0P1A_CNT_TARGET0_REACH_1_HP_INT_CLR — reg_0p1a_0 counter after xpd reach target0
  [15] PMU_0P1A_CNT_TARGET1_REACH_0_HP_INT_CLR — reg_0p1a_1_counter after xpd reach target1
  [14] PMU_0P1A_CNT_TARGET0_REACH_0_HP_INT_CLR — reg_0p1a_0_counter after xpd reach target0
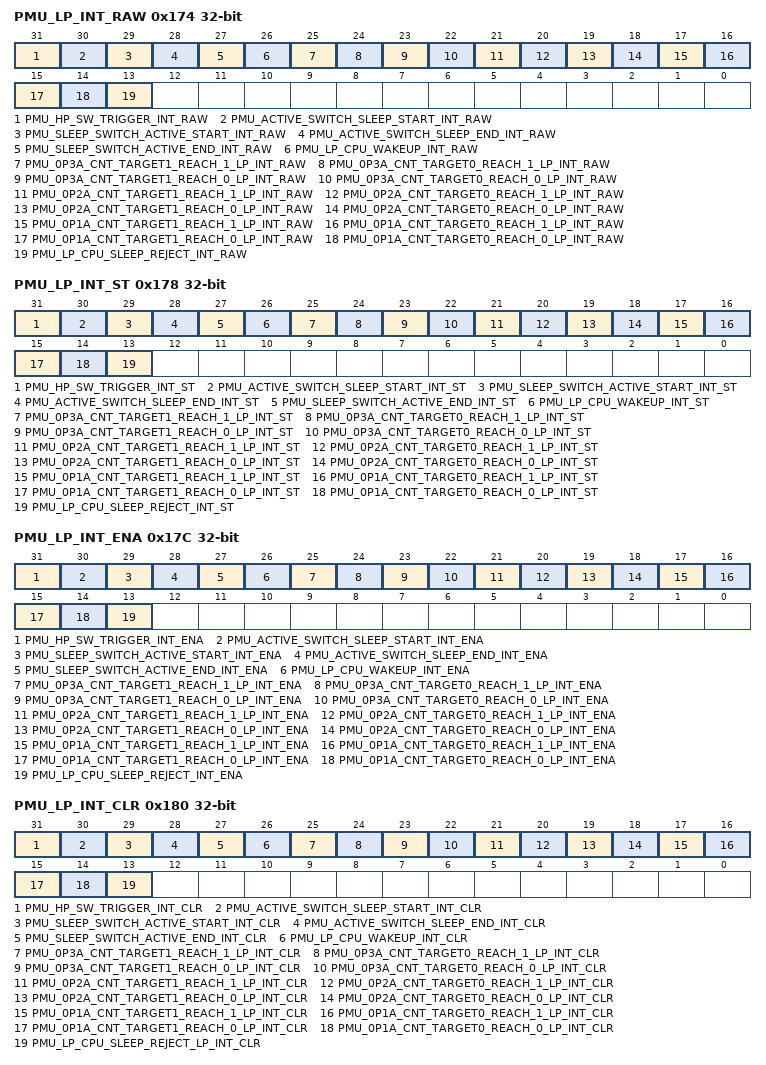
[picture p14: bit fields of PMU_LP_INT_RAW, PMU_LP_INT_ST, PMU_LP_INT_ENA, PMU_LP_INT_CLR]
0x174 PMU_LP_INT_RAW
  [31] PMU_HP_SW_TRIGGER_INT_RAW
  [30] PMU_ACTIVE_SWITCH_SLEEP_START_INT_RAW
  [29] PMU_SLEEP_SWITCH_ACTIVE_START_INT_RAW
  [28] PMU_ACTIVE_SWITCH_SLEEP_END_INT_RAW
  [27] PMU_SLEEP_SWITCH_ACTIVE_END_INT_RAW
  [26] PMU_LP_CPU_WAKEUP_INT_RAW
  [25] PMU_0P3A_CNT_TARGET1_REACH_1_LP_INT_RAW — reg_0p3a_1_counter after xpd reach target1
  [24] PMU_0P3A_CNT_TARGET0_REACH_1_LP_INT_RAW — reg_0p3a_0_counter after xpd reach target0
  [23] PMU_0P3A_CNT_TARGET1_REACH_0_LP_INT_RAW — reg_0p3a_1_counter after xpd reach target1
  [22] PMU_0P3A_CNT_TARGET0_REACH_0_LP_INT_RAW — reg_0p3a_0 counter after xpd reach target0
  [21] PMU_0P2A_CNT_TARGET1_REACH_1_LP_INT_RAW — reg_0p2a_1_counter after xpd reach target1
  [20] PMU_0P2A_CNT_TARGET0_REACH_1_LP_INT_RAW — reg_0p2a_0 counter after xpd reach target0
  [19] PMU_0P2A_CNT_TARGET1_REACH_0_LP_INT_RAW — reg_0p2a_1_counter after xpd reach target1
  [18] PMU_0P2A_CNT_TARGET0_REACH_0_LP_INT_RAW — reg_0p2a_0 counter after xpd reach target0
  [17] PMU_0P1A_CNT_TARGET1_REACH_1_LP_INT_RAW — reg_0p1a_1_counter after xpd reach target1
  [16] PMU_0P1A_CNT_TARGET0_REACH_1_LP_INT_RAW — reg_0p1a_0 counter after xpd reach target0
  [15] PMU_0P1A_CNT_TARGET1_REACH_0_LP_INT_RAW — reg_0p1a_1_counter after xpd reach target1
  [14] PMU_0P1A_CNT_TARGET0_REACH_0_LP_INT_RAW — reg_0p1a_0_counter after xpd reach target0
  [13] PMU_LP_CPU_SLEEP_REJECT_INT_RAW
0x178 PMU_LP_INT_ST ro
  [31] PMU_HP_SW_TRIGGER_INT_ST
  [30] PMU_ACTIVE_SWITCH_SLEEP_START_INT_ST
  [29] PMU_SLEEP_SWITCH_ACTIVE_START_INT_ST
  [28] PMU_ACTIVE_SWITCH_SLEEP_END_INT_ST
  [27] PMU_SLEEP_SWITCH_ACTIVE_END_INT_ST
  [26] PMU_LP_CPU_WAKEUP_INT_ST
  [25] PMU_0P3A_CNT_TARGET1_REACH_1_LP_INT_ST — reg_0p3a_1_counter after xpd reach target1
  [24] PMU_0P3A_CNT_TARGET0_REACH_1_LP_INT_ST — reg_0p3a_0_counter after xpd reach target0
  [23] PMU_0P3A_CNT_TARGET1_REACH_0_LP_INT_ST — reg_0p3a_1_counter after xpd reach target1
  [22] PMU_0P3A_CNT_TARGET0_REACH_0_LP_INT_ST — reg_0p3a_0 counter after xpd reach target0
  [21] PMU_0P2A_CNT_TARGET1_REACH_1_LP_INT_ST — reg_0p2a_1_counter after xpd reach target1
  [20] PMU_0P2A_CNT_TARGET0_REACH_1_LP_INT_ST — reg_0p2a_0 counter after xpd reach target0
  [19] PMU_0P2A_CNT_TARGET1_REACH_0_LP_INT_ST — reg_0p2a_1_counter after xpd reach target1
  [18] PMU_0P2A_CNT_TARGET0_REACH_0_LP_INT_ST — reg_0p2a_0 counter after xpd reach target0
  [17] PMU_0P1A_CNT_TARGET1_REACH_1_LP_INT_ST — reg_0p1a_1_counter after xpd reach target1
  [16] PMU_0P1A_CNT_TARGET0_REACH_1_LP_INT_ST — reg_0p1a_0 counter after xpd reach target0
  [15] PMU_0P1A_CNT_TARGET1_REACH_0_LP_INT_ST — reg_0p1a_1_counter after xpd reach target1
  [14] PMU_0P1A_CNT_TARGET0_REACH_0_LP_INT_ST — reg_0p1a_0_counter after xpd reach target0
  [13] PMU_LP_CPU_SLEEP_REJECT_INT_ST
0x17C PMU_LP_INT_ENA
  [31] PMU_HP_SW_TRIGGER_INT_ENA
  [30] PMU_ACTIVE_SWITCH_SLEEP_START_INT_ENA
  [29] PMU_SLEEP_SWITCH_ACTIVE_START_INT_ENA
  [28] PMU_ACTIVE_SWITCH_SLEEP_END_INT_ENA
  [27] PMU_SLEEP_SWITCH_ACTIVE_END_INT_ENA
  [26] PMU_LP_CPU_WAKEUP_INT_ENA
  [25] PMU_0P3A_CNT_TARGET1_REACH_1_LP_INT_ENA — reg_0p3a_1_counter after xpd reach target1
  [24] PMU_0P3A_CNT_TARGET0_REACH_1_LP_INT_ENA — reg_0p3a_0_counter after xpd reach target0
  [23] PMU_0P3A_CNT_TARGET1_REACH_0_LP_INT_ENA — reg_0p3a_1_counter after xpd reach target1
  [22] PMU_0P3A_CNT_TARGET0_REACH_0_LP_INT_ENA — reg_0p3a_0 counter after xpd reach target0
  [21] PMU_0P2A_CNT_TARGET1_REACH_1_LP_INT_ENA — reg_0p2a_1_counter after xpd reach target1
  [20] PMU_0P2A_CNT_TARGET0_REACH_1_LP_INT_ENA — reg_0p2a_0 counter after xpd reach target0
  [19] PMU_0P2A_CNT_TARGET1_REACH_0_LP_INT_ENA — reg_0p2a_1_counter after xpd reach target1
  [18] PMU_0P2A_CNT_TARGET0_REACH_0_LP_INT_ENA — reg_0p2a_0 counter after xpd reach target0
  [17] PMU_0P1A_CNT_TARGET1_REACH_1_LP_INT_ENA — reg_0p1a_1_counter after xpd reach target1
  [16] PMU_0P1A_CNT_TARGET0_REACH_1_LP_INT_ENA — reg_0p1a_0 counter after xpd reach target0
  [15] PMU_0P1A_CNT_TARGET1_REACH_0_LP_INT_ENA — reg_0p1a_1_counter after xpd reach target1
  [14] PMU_0P1A_CNT_TARGET0_REACH_0_LP_INT_ENA — reg_0p1a_0_counter after xpd reach target0
  [13] PMU_LP_CPU_SLEEP_REJECT_INT_ENA
0x180 PMU_LP_INT_CLR wo
  [31] PMU_HP_SW_TRIGGER_INT_CLR
  [30] PMU_ACTIVE_SWITCH_SLEEP_START_INT_CLR
  [29] PMU_SLEEP_SWITCH_ACTIVE_START_INT_CLR
  [28] PMU_ACTIVE_SWITCH_SLEEP_END_INT_CLR
  [27] PMU_SLEEP_SWITCH_ACTIVE_END_INT_CLR
  [26] PMU_LP_CPU_WAKEUP_INT_CLR
  [25] PMU_0P3A_CNT_TARGET1_REACH_1_LP_INT_CLR — reg_0p3a_1_counter after xpd reach target1
  [24] PMU_0P3A_CNT_TARGET0_REACH_1_LP_INT_CLR — reg_0p3a_0_counter after xpd reach target0
  [23] PMU_0P3A_CNT_TARGET1_REACH_0_LP_INT_CLR — reg_0p3a_1_counter after xpd reach target1
  [22] PMU_0P3A_CNT_TARGET0_REACH_0_LP_INT_CLR — reg_0p3a_0 counter after xpd reach target0
  [21] PMU_0P2A_CNT_TARGET1_REACH_1_LP_INT_CLR — reg_0p2a_1_counter after xpd reach target1
  [20] PMU_0P2A_CNT_TARGET0_REACH_1_LP_INT_CLR — reg_0p2a_0 counter after xpd reach target0
  [19] PMU_0P2A_CNT_TARGET1_REACH_0_LP_INT_CLR — reg_0p2a_1_counter after xpd reach target1
  [18] PMU_0P2A_CNT_TARGET0_REACH_0_LP_INT_CLR — reg_0p2a_0 counter after xpd reach target0
  [17] PMU_0P1A_CNT_TARGET1_REACH_1_LP_INT_CLR — reg_0p1a_1_counter after xpd reach target1
  [16] PMU_0P1A_CNT_TARGET0_REACH_1_LP_INT_CLR — reg_0p1a_0 counter after xpd reach target0
  [15] PMU_0P1A_CNT_TARGET1_REACH_0_LP_INT_CLR — reg_0p1a_1_counter after xpd reach target1
  [14] PMU_0P1A_CNT_TARGET0_REACH_0_LP_INT_CLR — reg_0p1a_0_counter after xpd reach target0
  [13] PMU_LP_CPU_SLEEP_REJECT_LP_INT_CLR
0x184 PMU_LP_CPU_PWR0 access per field
  [31] PMU_LP_CPU_SLP_BYPASS_INTR_EN rw, [30] PMU_LP_CPU_SLP_RESET_EN rw, [29] PMU_LP_CPU_SLP_STALL_EN rw, [28:21] PMU_LP_CPU_SLP_STALL_WAIT rw, [20] PMU_LP_CPU_SLP_STALL_FLAG_EN rw, [19] PMU_LP_CPU_SLP_WAITI_FLAG_EN rw, [18] PMU_LP_CPU_FORCE_STALL rw, [1] PMU_LP_CPU_STALL_RDY ro, [0] PMU_LP_CPU_WAITI_RDY ro
0x188 PMU_LP_CPU_PWR1 wo
  [31] PMU_LP_CPU_SLEEP_REQ
0x18C PMU_LP_CPU_PWR2
  [30:0] PMU_LP_CPU_WAKEUP_EN
0x190 PMU_LP_CPU_PWR3 ro
  [30:0] PMU_LP_CPU_WAKEUP_CAUSE
0x194 PMU_LP_CPU_PWR4
  [30:0] PMU_LP_CPU_REJECT_EN
0x198 PMU_LP_CPU_PWR5 ro
  [30:0] PMU_LP_CPU_REJECT_CAUSE
0x19C PMU_HP_LP_CPU_COMM wo
  [31] PMU_HP_TRIGGER_LP, [30] PMU_LP_TRIGGER_HP
0x1A0 PMU_HP_REGULATOR_CFG
  [31] PMU_DIG_REGULATOR_EN_CAL
0x1A4 PMU_MAIN_STATE access per field
  [31:25] PMU_PMU_MAIN_CUR_ST_STATE ro, [24:18] PMU_PMU_MAIN_TAR_ST_STATE ro, [17:11] PMU_PMU_MAIN_LAST_ST_STATE ro, [0] PMU_ENABLE_CALI_PMU_CNTL rw
0x1A8 PMU_PWR_STATE ro
  [31:23] PMU_PMU_HP_PWR_ST_STATE, [22:18] PMU_PMU_LP_PWR_ST_STATE, [17:13] PMU_PMU_BACKUP_ST_STATE
0x1AC PMU_CLK_STATE0 ro
  [31] PMU_PMU_ANA_XPD_XTAL_STATE, [30:27] PMU_PMU_ANA_XPD_PLL_STATE, [25] PMU_PMU_ANA_I2C_RETENTION_STATE, [24] PMU_PMU_ANA_I2C_ISO_EN_STATE, [23:20] PMU_PMU_ICG_GLOBAL_PLL_STATE, [19] PMU_PMU_ICG_GLOBAL_XTAL_STATE, [18] PMU_PMU_ICG_SLP_SEL_STATE, [17:16] PMU_PMU_ICG_MODEM_CODE_STATE, [15] PMU_PMU_ICG_MODEM_SWITCH_STATE, [14] PMU_PMU_ICG_SYS_CLK_EN_STATE, [13] PMU_PMU_SYS_CLK_NO_DIV_STATE, [12:11] PMU_PMU_SYS_CLK_SEL_STATE, [10] PMU_PMU_SYS_CLK_SLP_SEL_STATE, [6:4] PMU_PMU_ANA_XPD_PLL_I2C_STATE, [3] PMU_STABLE_XPD_XTAL_STATE, [2:0] PMU_STABLE_XPD_PLL_STATE
0x1B0 PMU_CLK_STATE1 ro
  [31:0] PMU_PMU_ICG_FUNC_EN_STATE
0x1B4 PMU_CLK_STATE2 ro
  [31:0] PMU_PMU_ICG_APB_EN_STATE
{0x1B0+8i} PMU_EXT_LDO_P0_0P{i}A access per field (i=1..3)
  [31] PMU_0P{i}A_LDO_CNT_PRESCALER_SEL_0 rw, [30:23] PMU_0P{i}A_TARGET0_0 rw, [22:15] PMU_0P{i}A_TARGET1_0 rw, [14] PMU_0P{i}A_TIEH_0 rw, [13] PMU_0P{i}A_TIEH_NEG_EN_0 rw, [12] PMU_0P{i}A_TIEH_POS_EN_0 rw, [11:9] PMU_0P{i}A_TIEH_SEL_0 rw, [8] PMU_0P{i}A_XPD_0 rw, [7] PMU_0P{i}A_FORCE_TIEH_SEL_0 rw, [6] PMU_0P{i}A_CNT_CLR_0 wo
{0x1B4+8i} PMU_EXT_LDO_P0_0P{i}A_ANA (i=1..3)
  [31:28] PMU_ANA_0P{i}A_DREF_0, [27] PMU_ANA_0P{i}A_EN_CUR_LIM_0, [26] PMU_ANA_0P{i}A_EN_VDET_0, [25:23] PMU_ANA_0P{i}A_MUL_0
{0x1C8+8i} PMU_EXT_LDO_P1_0P{i}A access per field (i=1..3)
  [31] PMU_0P{i}A_LDO_CNT_PRESCALER_SEL_1 rw, [30:23] PMU_0P{i}A_TARGET0_1 rw, [22:15] PMU_0P{i}A_TARGET1_1 rw, [14] PMU_0P{i}A_TIEH_1 rw, [13] PMU_0P{i}A_TIEH_NEG_EN_1 rw, [12] PMU_0P{i}A_TIEH_POS_EN_1 rw, [11:9] PMU_0P{i}A_TIEH_SEL_1 rw, [8] PMU_0P{i}A_XPD_1 rw, [7] PMU_0P{i}A_FORCE_TIEH_SEL_1 rw, [6] PMU_0P{i}A_CNT_CLR_1 wo
{0x1CC+8i} PMU_EXT_LDO_P1_0P{i}A_ANA (i=1..3)
  [31:28] PMU_ANA_0P{i}A_DREF_1, [27] PMU_ANA_0P{i}A_EN_CUR_LIM_1, [26] PMU_ANA_0P{i}A_EN_VDET_1, [25:23] PMU_ANA_0P{i}A_MUL_1
0x1E8 PMU_EXT_WAKEUP_LV
0x1EC PMU_EXT_WAKEUP_SEL
0x1F0 PMU_EXT_WAKEUP_ST ro
  [31:0] PMU_EXT_WAKEUP_STATUS
0x1F4 PMU_EXT_WAKEUP_CNTL
  [31] PMU_EXT_WAKEUP_FILTER, [30] PMU_EXT_WAKEUP_STATUS_CLR
0x1F8 PMU_SDIO_WAKEUP_CNTL
  [9:0] PMU_SDIO_ACT_DNUM
0x1FC PMU_XTAL_SLP
  [31:16] PMU_XTAL_SLP_CNT_TARGET
0x200 PMU_CPU_SW_STALL
  [31:24] PMU_HPCORE0_SW_STALL_CODE, [23:16] PMU_HPCORE1_SW_STALL_CODE
0x204 PMU_DCM_CTRL access per field
  [29] PMU_DCDC_EN_AMUX_TEST rw — Enable analog mux to pull PAD TEST_DCDC voltage signal
  [23:16] PMU_DCM_CUR_ST ro
  [15] PMU_DCDC_DS_FORCE_PD rw
  [14] PMU_DCDC_DS_FORCE_PU rw
  [13] PMU_DCDC_LS_FORCE_PD rw
  [12] PMU_DCDC_LS_FORCE_PU rw
  [11] PMU_DCDC_FB_RES_FORCE_PD rw
  [10] PMU_DCDC_FB_RES_FORCE_PU rw
  [9] PMU_DCDC_ON_FORCE_PD rw
  [8] PMU_DCDC_ON_FORCE_PU rw
  [7] PMU_DCDC_DONE_FORCE rw
  [3] PMU_DCDC_DEEPSLP_REQ wo — SW trigger dcdc enter deepsleep
  [2] PMU_DCDC_LIGHTSLP_REQ wo — SW trigger dcdc enter lightsleep
  [1] PMU_DCDC_OFF_REQ wo — SW trigger dcdc off
  [0] PMU_DCDC_ON_REQ wo — SW trigger dcdc on
0x208 PMU_DCM_WAIT_DELAY
  [25:16] PMU_DCDC_STABLE_DELAY — DCDC stable delay
  [15:8] PMU_DCDC_RES_OFF_DELAY — DCDC fb res off delay
  [7:0] PMU_DCDC_PRE_DELAY — DCDC pre-on/post off delay
0x20C PMU_VDDBAT_CFG access per field
  [31] PMU_VDDBAT_SW_UPDATE wo, [1:0] PMU_ANA_VDDBAT_MODE ro
0x210 PMU_TOUCH_PWR_CNTL
  [31] PMU_TOUCH_SLEEP_TIMER_EN, [30] PMU_TOUCH_FORCE_DONE, [29:14] PMU_TOUCH_SLEEP_CYCLES, [13:5] PMU_TOUCH_WAIT_CYCLES
0x214 PMU_RDN_ECO access per field
  [31] PMU_PMU_RDN_ECO_EN rw, [0] PMU_PMU_RDN_ECO_RESULT ro
0x218 PMU_POWER_PD_HP_CPU_CNTL
  [5] PMU_FORCE_HP_CPU_PD, [4] PMU_FORCE_HP_CPU_NO_ISO, [3] PMU_FORCE_HP_CPU_NO_RESET, [2] PMU_FORCE_HP_CPU_PU, [1] PMU_FORCE_HP_CPU_ISO, [0] PMU_FORCE_HP_CPU_RESET
0x21C PMU_POWER_PD_HP_CPU_MASK
  [31:27] PMU_PD_HP_CPU_MASK, [4:0] PMU_XPD_HP_CPU_MASK
0x3FC PMU_DATE
  [31] PMU_CLK_EN, [30:0] PMU_PMU_DATE
